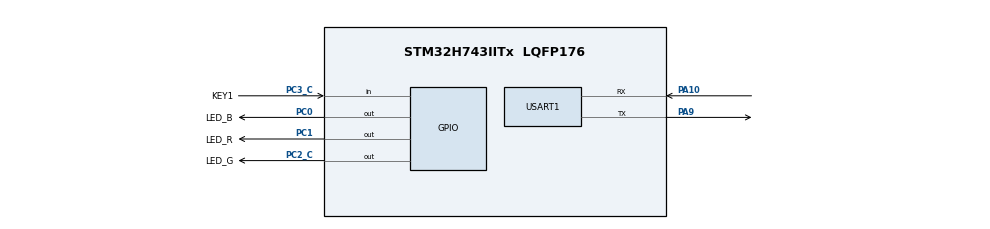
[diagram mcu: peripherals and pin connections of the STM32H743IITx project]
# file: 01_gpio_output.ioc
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CORTEX_M7.Enable_Spec=__NULL
CORTEX_M7.default_mode_Activation=1
Mcu.Family=STM32H7
Mcu.Name=STM32H743IITx
Mcu.Package=LQFP176
NVIC.PriorityGroup=NVIC_PRIORITYGROUP_4
NVIC.USART1_IRQn=true\:0\:0\:false\:false\:true\:true\:true\:true
PA10.Mode=Asynchronous
PA10.Signal=USART1_RX
PA13\ (JTMS/SWDIO).Mode=Serial_Wire
PA13\ (JTMS/SWDIO).Signal=DEBUG_JTMS-SWDIO
PA14\ (JTCK/SWCLK).Mode=Serial_Wire
PA14\ (JTCK/SWCLK).Signal=DEBUG_JTCK-SWCLK
PA9.Mode=Asynchronous
PA9.Signal=USART1_TX
PC0.GPIO_Label=LED_B
PC0.GPIO_ModeDefaultOutputPP=GPIO_MODE_OUTPUT_PP
PC0.GPIO_PuPd=GPIO_NOPULL
PC0.GPIO_Speed=GPIO_SPEED_FREQ_LOW
PC0.PinState=GPIO_PIN_RESET
PC0.Signal=GPIO_Output
PC1.GPIO_Label=LED_R
PC1.PinState=GPIO_PIN_RESET
PC1.Signal=GPIO_Output
PC2_C.GPIO_Label=LED_G
PC2_C.PinState=GPIO_PIN_RESET
PC2_C.Signal=GPIO_Output
PC3_C.GPIO_Label=KEY1
PC3_C.GPIO_PuPd=GPIO_PULLUP
PC3_C.Signal=GPIO_Input
PH0-OSC_IN\ (PH0).Mode=HSE-External-Oscillator
PH0-OSC_IN\ (PH0).Signal=RCC_OSC_IN
PH1-OSC_OUT\ (PH1).Mode=HSE-External-Oscillator
PH1-OSC_OUT\ (PH1).Signal=RCC_OSC_OUT
ProjectManager.HeapSize=0x200
ProjectManager.StackSize=0x400
ProjectManager.TargetToolchain=CMake
RCC.ADCFreq_Value=50390625
RCC.APB1Freq_Value=120000000
RCC.APB2Freq_Value=120000000
RCC.APB3Freq_Value=120000000
RCC.APB4Freq_Value=120000000
RCC.CortexFreq_Value=480000000
RCC.D1PPRE=RCC_APB3_DIV2
RCC.D2PPRE1=RCC_APB1_DIV2
RCC.D2PPRE2=RCC_APB2_DIV2
RCC.D3PPRE=RCC_APB4_DIV2
RCC.DIVM1=5
RCC.DIVN1=192
RCC.HCLKFreq_Value=240000000
RCC.HPRE=RCC_HCLK_DIV2
RCC.HSE_VALUE=25000000
RCC.PLLFRACN=0
RCC.PLLSourceVirtual=RCC_PLLSOURCE_HSE
RCC.SYSCLKFreq_VALUE=480000000
RCC.SYSCLKSource=RCC_SYSCLKSOURCE_PLLCLK
RCC.USBFreq_Value=480000000
USART1.VirtualMode-Asynchronous=VM_ASYNC
VP_MEMORYMAP_VS_MEMORYMAP.Mode=CurAppReg
board=custom

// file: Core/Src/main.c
/* USER CODE BEGIN Header */
/**
  ******************************************************************************
  * @file           : main.c
  * @brief          : Main program body
  ******************************************************************************
  * @attention
  *
  * Copyright (c) 2025 STMicroelectronics.
  * All rights reserved.
  *
  * This software is licensed under terms that can be found in the LICENSE file
  * in the root directory of this software component.
  * If no LICENSE file comes with this software, it is provided AS-IS.
  *
  ******************************************************************************
  */
/* USER CODE END Header */
#include "main.h"
#include "memorymap.h"
#include "usart.h"
#include "gpio.h"

/* USER CODE BEGIN Includes */
#include <string.h>
#include <stdio.h>
/* USER CODE END Includes */

void SystemClock_Config(void);
static void MPU_Config(void);

/* USER CODE BEGIN 0 */
// #define RXBUFFERSIZE 30
// uint8_t aRxBuffer[RXBUFFERSIZE] __attribute__((section(".dma_buffer")));

// void HAL_UARTEx_RxEventCallback(UART_HandleTypeDef *huart,uint16_t size) {
//   if (huart->Instance == USART1) {
//     HAL_UART_DMAStop(huart);
//     // uint16_t size = RXBUFFERSIZE - __HAL_DMA_GET_COUNTER(huart->hdmarx);
//     // HAL_UART_ReceiveToIdle_DMA(huart, aRxBuffer, RXBUFFERSIZE);
//     // HAL_UART_Transmit(&huart1, aRxBuffer, size, 1000);
//     HAL_GPIO_TogglePin(LED_G_GPIO_Port, LED_G_Pin);
//   }
//
//
// }
uint8_t tx_buffer[30];

uint8_t rx_buffer[30];
void HAL_UARTEx_RxEventCallback(UART_HandleTypeDef *huart,uint16_t size) {
  if (huart->Instance == USART1) {
    HAL_UARTEx_ReceiveToIdle_IT(huart, rx_buffer, 10);
    // HAL_GPIO_TogglePin(LED_G_GPIO_Port, LED_G_Pin);
    sprintf((char *)tx_buffer,"%s",(char *)rx_buffer);
    HAL_UART_Transmit_IT(&huart1,tx_buffer,strlen(tx_buffer));
  }

}

/* USER CODE END 0 */

int main(void)
{

  /* MPU Configuration--------------------------------------------------------*/
  MPU_Config();

  /* MCU Configuration--------------------------------------------------------*/

  /* Reset of all peripherals, Initializes the Flash interface and the Systick. */
  HAL_Init();

  /* Configure the system clock */
  SystemClock_Config();

  /* Initialize all configured peripherals */
  MX_GPIO_Init();
  MX_USART1_UART_Init();
  /* USER CODE BEGIN 2 */

  // HAL_UART_Receive(&huart1,rx_buffer,10,5000);
  //

  HAL_UARTEx_ReceiveToIdle_IT(&huart1,rx_buffer,10);

  // char buff[30];
  // uint8_t len =30;
  // while (len) {
  //   HAL_UART_Transmit(&huart1,buff+(30-len),1,30);
  //   HAL_Delay(10);
  //   len--;
  // }

  /*
   *
  *
  *
void HAL_GPIO_WritePin(GPIO_TypeDef *GPIOx, uint16_t GPIO_Pin, GPIO_PinState PinState);
void HAL_GPIO_TogglePin(GPIO_TypeDef *GPIOx, uint16_t GPIO_Pin);
#define LED_B_Pin GPIO_PIN_0
#define LED_B_GPIO_Port GPIOC
#define LED_R_Pin GPIO_PIN_1
#define LED_R_GPIO_Port GPIOC
#define LED_G_Pin GPIO_PIN_2
#define LED_G_GPIO_Port GPIOC
   *
   */

  /* USER CODE END 2 */

  /* Infinite loop */
  /* USER CODE BEGIN WHILE */
  while (1)
  {
    // HAL_GPIO_TogglePin(LED_B_GPIO_Port,LED_B_Pin);
    // HAL_Delay(1000);
    // HAL_GPIO_TogglePin(LED_G_GPIO_Port, LED_G_Pin);
    // HAL_Delay(1000);
    // HAL_GPIO_TogglePin(LED_R_GPIO_Port, LED_R_Pin);
    // HAL_Delay(1000);

    // if (HAL_GPIO_ReadPin(KEY1_GPIO_Port, KEY1_Pin) == GPIO_PIN_RESET)
    // {
    //   HAL_GPIO_WritePin(LED_G_GPIO_Port, LED_G_Pin, GPIO_PIN_SET);
    // }
    // else
    // {
    //   HAL_GPIO_WritePin(LED_G_GPIO_Port, LED_G_Pin, GPIO_PIN_RESET);
    // }
    /* USER CODE END WHILE */

  }
}

void SystemClock_Config(void)
{
  RCC_OscInitTypeDef RCC_OscInitStruct = {0};
  RCC_ClkInitTypeDef RCC_ClkInitStruct = {0};

  /** Supply configuration update enable
  */
  HAL_PWREx_ConfigSupply(PWR_LDO_SUPPLY);

  /** Configure the main internal regulator output voltage
  */
  __HAL_PWR_VOLTAGESCALING_CONFIG(PWR_REGULATOR_VOLTAGE_SCALE0);

  while(!__HAL_PWR_GET_FLAG(PWR_FLAG_VOSRDY)) {}

  /** Initializes the RCC Oscillators according to the specified parameters
  * in the RCC_OscInitTypeDef structure.
  */
  RCC_OscInitStruct.OscillatorType = RCC_OSCILLATORTYPE_HSE;
  RCC_OscInitStruct.HSEState = RCC_HSE_ON;
  RCC_OscInitStruct.PLL.PLLState = RCC_PLL_ON;
  RCC_OscInitStruct.PLL.PLLSource = RCC_PLLSOURCE_HSE;
  RCC_OscInitStruct.PLL.PLLM = 5;
  RCC_OscInitStruct.PLL.PLLN = 192;
  RCC_OscInitStruct.PLL.PLLP = 2;
  RCC_OscInitStruct.PLL.PLLQ = 2;
  RCC_OscInitStruct.PLL.PLLR = 2;
  RCC_OscInitStruct.PLL.PLLRGE = RCC_PLL1VCIRANGE_2;
  RCC_OscInitStruct.PLL.PLLVCOSEL = RCC_PLL1VCOWIDE;
  RCC_OscInitStruct.PLL.PLLFRACN = 0;
  if (HAL_RCC_OscConfig(&RCC_OscInitStruct) != HAL_OK)
  {
    Error_Handler();
  }

  /** Initializes the CPU, AHB and APB buses clocks
  */
  RCC_ClkInitStruct.ClockType = RCC_CLOCKTYPE_HCLK|RCC_CLOCKTYPE_SYSCLK
                              |RCC_CLOCKTYPE_PCLK1|RCC_CLOCKTYPE_PCLK2
                              |RCC_CLOCKTYPE_D3PCLK1|RCC_CLOCKTYPE_D1PCLK1;
  RCC_ClkInitStruct.SYSCLKSource = RCC_SYSCLKSOURCE_PLLCLK;
  RCC_ClkInitStruct.SYSCLKDivider = RCC_SYSCLK_DIV1;
  RCC_ClkInitStruct.AHBCLKDivider = RCC_HCLK_DIV2;
  RCC_ClkInitStruct.APB3CLKDivider = RCC_APB3_DIV2;
  RCC_ClkInitStruct.APB1CLKDivider = RCC_APB1_DIV2;
  RCC_ClkInitStruct.APB2CLKDivider = RCC_APB2_DIV2;
  RCC_ClkInitStruct.APB4CLKDivider = RCC_APB4_DIV2;

  if (HAL_RCC_ClockConfig(&RCC_ClkInitStruct, FLASH_LATENCY_4) != HAL_OK)
  {
    Error_Handler();
  }
}

 /* MPU Configuration */

void MPU_Config(void)
{

  /* Disables the MPU */
  HAL_MPU_Disable();

  /* Enables the MPU */
  HAL_MPU_Enable(MPU_PRIVILEGED_DEFAULT);

}

void Error_Handler(void)
{
  __disable_irq();
  while (1)
  {
  }
}
